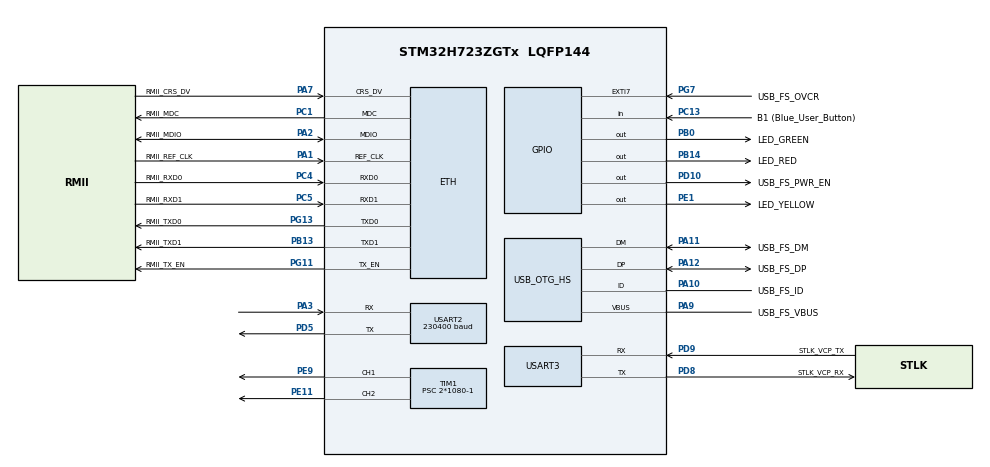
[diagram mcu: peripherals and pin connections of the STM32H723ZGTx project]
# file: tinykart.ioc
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Dma.Request0=USART2_RX
Dma.USART2_RX.0.Direction=DMA_PERIPH_TO_MEMORY
Dma.USART2_RX.0.EventEnable=DISABLE
Dma.USART2_RX.0.FIFOMode=DMA_FIFOMODE_DISABLE
Dma.USART2_RX.0.Instance=DMA1_Stream0
Dma.USART2_RX.0.MemDataAlignment=DMA_MDATAALIGN_BYTE
Dma.USART2_RX.0.MemInc=DMA_MINC_ENABLE
Dma.USART2_RX.0.Mode=DMA_NORMAL
Dma.USART2_RX.0.PeriphDataAlignment=DMA_PDATAALIGN_BYTE
Dma.USART2_RX.0.PeriphInc=DMA_PINC_DISABLE
Dma.USART2_RX.0.Polarity=HAL_DMAMUX_REQ_GEN_RISING
Dma.USART2_RX.0.Priority=DMA_PRIORITY_LOW
Dma.USART2_RX.0.RequestNumber=1
Dma.USART2_RX.0.SignalID=NONE
Dma.USART2_RX.0.SyncEnable=DISABLE
Dma.USART2_RX.0.SyncPolarity=HAL_DMAMUX_SYNC_NO_EVENT
Dma.USART2_RX.0.SyncRequestNumber=1
Dma.USART2_RX.0.SyncSignalID=NONE
ETH.MediaInterface=HAL_ETH_RMII_MODE
Mcu.Family=STM32H7
Mcu.Name=STM32H723ZGTx
Mcu.Package=LQFP144
NVIC.DMA1_Stream0_IRQn=true\:0\:0\:false\:false\:true\:false\:true\:true
NVIC.PriorityGroup=NVIC_PRIORITYGROUP_4
NVIC.USART2_IRQn=true\:0\:0\:false\:false\:true\:true\:true\:true
PA1.GPIO_Label=RMII_REF_CLK
PA1.Mode=RMII
PA1.Signal=ETH_REF_CLK
PA10.GPIO_Label=USB_FS_ID
PA10.Mode=OTG/Dual-Role-Device-FS
PA10.Signal=USB_OTG_HS_ID
PA11.GPIO_Label=USB_FS_DM
PA11.Mode=OTG/Dual-Role-Device-FS
PA11.Signal=USB_OTG_HS_DM
PA12.GPIO_Label=USB_FS_DP
PA12.Mode=OTG/Dual-Role-Device-FS
PA12.Signal=USB_OTG_HS_DP
PA13(JTMS/SWDIO).GPIO_Label=SWDIO
PA13(JTMS/SWDIO).Mode=Trace_Asynchronous_SW
PA13(JTMS/SWDIO).Signal=DEBUG_JTMS-SWDIO
PA14(JTCK/SWCLK).GPIO_Label=SWCLK
PA14(JTCK/SWCLK).Mode=Trace_Asynchronous_SW
PA14(JTCK/SWCLK).Signal=DEBUG_JTCK-SWCLK
PA2.GPIO_Label=RMII_MDIO
PA2.Mode=RMII
PA2.Signal=ETH_MDIO
PA3.Mode=Asynchronous
PA3.Signal=USART2_RX
PA7.GPIO_Label=RMII_CRS_DV
PA7.Mode=RMII
PA7.Signal=ETH_CRS_DV
PA9.GPIO_Label=USB_FS_VBUS
PA9.Mode=Activate_VBUS_FS
PA9.Signal=USB_OTG_HS_VBUS
PB0.GPIO_Label=LED_GREEN
PB0.Signal=GPIO_Output
PB13.GPIO_Label=RMII_TXD1
PB13.Mode=RMII
PB13.Signal=ETH_TXD1
PB14.GPIO_Label=LED_RED
PB14.Signal=GPIO_Output
PB3(JTDO/TRACESWO).GPIO_Label=SWO
PB3(JTDO/TRACESWO).Mode=Trace_Asynchronous_SW
PB3(JTDO/TRACESWO).Signal=DEBUG_JTDO-SWO
PC1.GPIO_Label=RMII_MDC
PC1.Mode=RMII
PC1.Signal=ETH_MDC
PC13.GPIO_Label=B1 (Blue_User_Button)
PC13.Signal=GPIO_Input
PC14-OSC32_IN.Mode=LSE-External-Oscillator
PC14-OSC32_IN.Signal=RCC_OSC32_IN
PC15-OSC32_OUT.Mode=LSE-External-Oscillator
PC15-OSC32_OUT.Signal=RCC_OSC32_OUT
PC4.GPIO_Label=RMII_RXD0
PC4.Mode=RMII
PC4.Signal=ETH_RXD0
PC5.GPIO_Label=RMII_RXD1
PC5.Mode=RMII
PC5.Signal=ETH_RXD1
PD10.GPIO_Label=USB_FS_PWR_EN
PD10.Signal=GPIO_Output
PD5.Mode=Asynchronous
PD5.Signal=USART2_TX
PD8.GPIO_Label=STLK_VCP_RX
PD8.Mode=Asynchronous
PD8.Signal=USART3_TX
PD9.GPIO_Label=STLK_VCP_TX
PD9.Mode=Asynchronous
PD9.Signal=USART3_RX
PE1.GPIO_Label=LED_YELLOW
PE1.Signal=GPIO_Output
PE11.Signal=S_TIM1_CH2
PE9.Signal=S_TIM1_CH1
PG11.GPIO_Label=RMII_TX_EN
PG11.Mode=RMII
PG11.Signal=ETH_TX_EN
PG13.GPIO_Label=RMII_TXD0
PG13.Mode=RMII
PG13.Signal=ETH_TXD0
PG7.GPIO_Label=USB_FS_OVCR
PG7.Signal=GPXTI7
PH0-OSC_IN.GPIO_Label=MCO
PH0-OSC_IN.Mode=HSE-External-Oscillator
PH0-OSC_IN.Signal=RCC_OSC_IN
PH1-OSC_OUT.Mode=HSE-External-Oscillator
PH1-OSC_OUT.Signal=RCC_OSC_OUT
ProjectManager.HeapSize=0x200
ProjectManager.StackSize=0x400
ProjectManager.TargetToolchain=STM32CubeIDE
RCC.ADCFreq_Value=76000000
RCC.APB1Freq_Value=54000000
RCC.APB2Freq_Value=108000000
RCC.APB3Freq_Value=108000000
RCC.APB4Freq_Value=108000000
RCC.CortexFreq_Value=216000000
RCC.D1PPRE=RCC_APB3_DIV2
RCC.D2PPRE1=RCC_APB1_DIV4
RCC.D2PPRE2=RCC_APB2_DIV2
RCC.D3PPRE=RCC_APB4_DIV2
RCC.DIVM1=1
RCC.DIVM2=1
RCC.DIVN1=27
RCC.DIVN2=19
RCC.DIVP1=1
RCC.DIVQ1=4
RCC.HCLKFreq_Value=216000000
RCC.HSE_VALUE=8000000
RCC.PLLFRACN=0
RCC.PLLSourceVirtual=RCC_PLLSOURCE_HSE
RCC.SYSCLKFreq_VALUE=216000000
RCC.SYSCLKSource=RCC_SYSCLKSOURCE_PLLCLK
RCC.USBCLockSelection=RCC_USBCLKSOURCE_HSI48
RCC.USBFreq_Value=48000000
SH.S_TIM1_CH1.0=TIM1_CH1,PWM Generation1 CH1
SH.S_TIM1_CH2.0=TIM1_CH2,PWM Generation2 CH2
TIM1.Channel-PWM\ Generation1\ CH1=TIM_CHANNEL_1
TIM1.Channel-PWM\ Generation2\ CH2=TIM_CHANNEL_2
TIM1.Period=1000-1
TIM1.Prescaler=2*1080-1
USART2.BaudRate=230400
USART2.VirtualMode-Asynchronous=VM_ASYNC
USART3.VirtualMode-Asynchronous=VM_ASYNC
board=NUCLEO-H723ZG

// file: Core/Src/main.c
/* USER CODE BEGIN Header */
/**
 ******************************************************************************
 * @file           : main.c
 * @brief          : Main program body
 ******************************************************************************
 * @attention
 *
 * Copyright (c) 2023 STMicroelectronics.
 * All rights reserved.
 *
 * This software is licensed under terms that can be found in the LICENSE file
 * in the root directory of this software component.
 * If no LICENSE file comes with this software, it is provided AS-IS.
 *
 ******************************************************************************
 */
/* USER CODE END Header */
#include "main.h"
#include "string.h"
#include <stdio.h>

#if defined ( __ICCARM__ ) /*!< IAR Compiler */
#pragma location=0x30000000
ETH_DMADescTypeDef  DMARxDscrTab[ETH_RX_DESC_CNT]; /* Ethernet Rx DMA Descriptors */
#pragma location=0x30000200
ETH_DMADescTypeDef  DMATxDscrTab[ETH_TX_DESC_CNT]; /* Ethernet Tx DMA Descriptors */

#elif defined ( __CC_ARM )  /* MDK ARM Compiler */

__attribute__((at(0x30000000))) ETH_DMADescTypeDef  DMARxDscrTab[ETH_RX_DESC_CNT]; /* Ethernet Rx DMA Descriptors */
__attribute__((at(0x30000200))) ETH_DMADescTypeDef  DMATxDscrTab[ETH_TX_DESC_CNT]; /* Ethernet Tx DMA Descriptors */

#elif defined ( __GNUC__ ) /* GNU Compiler */
ETH_DMADescTypeDef DMARxDscrTab[ETH_RX_DESC_CNT] __attribute__((section(".RxDecripSection"))); /* Ethernet Rx DMA Descriptors */
ETH_DMADescTypeDef DMATxDscrTab[ETH_TX_DESC_CNT] __attribute__((section(".TxDecripSection"))); /* Ethernet Tx DMA Descriptors */

#endif

ETH_TxPacketConfig TxConfig;

ETH_HandleTypeDef heth;

TIM_HandleTypeDef htim1;

UART_HandleTypeDef huart2;
UART_HandleTypeDef huart3;
DMA_HandleTypeDef hdma_usart2_rx;

void SystemClock_Config(void);
static void MX_GPIO_Init(void);
static void MX_DMA_Init(void);
static void MX_USART3_UART_Init(void);
static void MX_USB_OTG_HS_USB_Init(void);
static void MX_TIM1_Init(void);
static void MX_USART2_UART_Init(void);
static void MX_ETH_Init(void);

/* USER CODE BEGIN 0 */

uint8_t rx_indx;
uint8_t rx_data[11];
uint8_t rx_buffer[47];
uint8_t transfer_cplt;

int _write(int file, char *ptr, int len) {
		HAL_UART_Transmit(&huart2, (uint8_t*)ptr, len, HAL_MAX_DELAY);
		return len;
}

/* USER CODE END 0 */

int main(void) {

	/* MCU Configuration--------------------------------------------------------*/

	/* Reset of all peripherals, Initializes the Flash interface and the Systick. */
	HAL_Init();

	/* USER CODE BEGIN Init */
	HAL_TIM_PWM_Start(&htim1, 1);

	/* USER CODE END Init */

	/* Configure the system clock */
	SystemClock_Config();

	/* Initialize all configured peripherals */
	MX_GPIO_Init();
	MX_DMA_Init();
	MX_USART3_UART_Init();
	MX_USB_OTG_HS_USB_Init();
	MX_TIM1_Init();
	MX_USART2_UART_Init();
	MX_ETH_Init();

	/* Infinite loop */
	while (1) {

		HAL_UART_Receive_DMA(&huart2, rx_buffer, 47);

		printf("hi");
		HAL_Delay(500);

	}
}

void SystemClock_Config(void) {
	RCC_OscInitTypeDef RCC_OscInitStruct = { 0 };
	RCC_ClkInitTypeDef RCC_ClkInitStruct = { 0 };

	/** Supply configuration update enable
	 */
	HAL_PWREx_ConfigSupply(PWR_LDO_SUPPLY);

	/** Configure the main internal regulator output voltage
	 */
	__HAL_PWR_VOLTAGESCALING_CONFIG(PWR_REGULATOR_VOLTAGE_SCALE2);

	while (!__HAL_PWR_GET_FLAG(PWR_FLAG_VOSRDY)) {
	}

	/** Initializes the RCC Oscillators according to the specified parameters
	 * in the RCC_OscInitTypeDef structure.
	 */
	RCC_OscInitStruct.OscillatorType = RCC_OSCILLATORTYPE_HSI48
			| RCC_OSCILLATORTYPE_HSE;
	RCC_OscInitStruct.HSEState = RCC_HSE_ON;
	RCC_OscInitStruct.HSI48State = RCC_HSI48_ON;
	RCC_OscInitStruct.PLL.PLLState = RCC_PLL_ON;
	RCC_OscInitStruct.PLL.PLLSource = RCC_PLLSOURCE_HSE;
	RCC_OscInitStruct.PLL.PLLM = 1;
	RCC_OscInitStruct.PLL.PLLN = 27;
	RCC_OscInitStruct.PLL.PLLP = 1;
	RCC_OscInitStruct.PLL.PLLQ = 4;
	RCC_OscInitStruct.PLL.PLLR = 2;
	RCC_OscInitStruct.PLL.PLLRGE = RCC_PLL1VCIRANGE_3;
	RCC_OscInitStruct.PLL.PLLVCOSEL = RCC_PLL1VCOWIDE;
	RCC_OscInitStruct.PLL.PLLFRACN = 0;
	if (HAL_RCC_OscConfig(&RCC_OscInitStruct) != HAL_OK) {
		Error_Handler();
	}

	/** Initializes the CPU, AHB and APB buses clocks
	 */
	RCC_ClkInitStruct.ClockType = RCC_CLOCKTYPE_HCLK | RCC_CLOCKTYPE_SYSCLK
			| RCC_CLOCKTYPE_PCLK1 | RCC_CLOCKTYPE_PCLK2 | RCC_CLOCKTYPE_D3PCLK1
			| RCC_CLOCKTYPE_D1PCLK1;
	RCC_ClkInitStruct.SYSCLKSource = RCC_SYSCLKSOURCE_PLLCLK;
	RCC_ClkInitStruct.SYSCLKDivider = RCC_SYSCLK_DIV1;
	RCC_ClkInitStruct.AHBCLKDivider = RCC_HCLK_DIV1;
	RCC_ClkInitStruct.APB3CLKDivider = RCC_APB3_DIV2;
	RCC_ClkInitStruct.APB1CLKDivider = RCC_APB1_DIV4;
	RCC_ClkInitStruct.APB2CLKDivider = RCC_APB2_DIV2;
	RCC_ClkInitStruct.APB4CLKDivider = RCC_APB4_DIV2;

	if (HAL_RCC_ClockConfig(&RCC_ClkInitStruct, FLASH_LATENCY_0) != HAL_OK) {
		Error_Handler();
	}
}

static void MX_ETH_Init(void) {

	static uint8_t MACAddr[6];

	heth.Instance = ETH;
	MACAddr[0] = 0x00;
	MACAddr[1] = 0x80;
	MACAddr[2] = 0xE1;
	MACAddr[3] = 0x00;
	MACAddr[4] = 0x00;
	MACAddr[5] = 0x00;
	heth.Init.MACAddr = &MACAddr[0];
	heth.Init.MediaInterface = HAL_ETH_RMII_MODE;
	heth.Init.TxDesc = DMATxDscrTab;
	heth.Init.RxDesc = DMARxDscrTab;
	heth.Init.RxBuffLen = 1524;

	if (HAL_ETH_Init(&heth) != HAL_OK) {
		Error_Handler();
	}

	memset(&TxConfig, 0, sizeof(ETH_TxPacketConfig));
	TxConfig.Attributes = ETH_TX_PACKETS_FEATURES_CSUM
			| ETH_TX_PACKETS_FEATURES_CRCPAD;
	TxConfig.ChecksumCtrl = ETH_CHECKSUM_IPHDR_PAYLOAD_INSERT_PHDR_CALC;
	TxConfig.CRCPadCtrl = ETH_CRC_PAD_INSERT;

}

static void MX_TIM1_Init(void) {

	TIM_MasterConfigTypeDef sMasterConfig = { 0 };
	TIM_OC_InitTypeDef sConfigOC = { 0 };
	TIM_BreakDeadTimeConfigTypeDef sBreakDeadTimeConfig = { 0 };

	htim1.Instance = TIM1;
	htim1.Init.Prescaler = 2 * 1080 - 1;
	htim1.Init.CounterMode = TIM_COUNTERMODE_UP;
	htim1.Init.Period = 1000 - 1;
	htim1.Init.ClockDivision = TIM_CLOCKDIVISION_DIV1;
	htim1.Init.RepetitionCounter = 0;
	htim1.Init.AutoReloadPreload = TIM_AUTORELOAD_PRELOAD_DISABLE;
	if (HAL_TIM_PWM_Init(&htim1) != HAL_OK) {
		Error_Handler();
	}
	sMasterConfig.MasterOutputTrigger = TIM_TRGO_RESET;
	sMasterConfig.MasterOutputTrigger2 = TIM_TRGO2_RESET;
	sMasterConfig.MasterSlaveMode = TIM_MASTERSLAVEMODE_DISABLE;
	if (HAL_TIMEx_MasterConfigSynchronization(&htim1, &sMasterConfig)
			!= HAL_OK) {
		Error_Handler();
	}
	sConfigOC.OCMode = TIM_OCMODE_PWM1;
	sConfigOC.Pulse = 0;
	sConfigOC.OCPolarity = TIM_OCPOLARITY_HIGH;
	sConfigOC.OCNPolarity = TIM_OCNPOLARITY_HIGH;
	sConfigOC.OCFastMode = TIM_OCFAST_DISABLE;
	sConfigOC.OCIdleState = TIM_OCIDLESTATE_RESET;
	sConfigOC.OCNIdleState = TIM_OCNIDLESTATE_RESET;
	if (HAL_TIM_PWM_ConfigChannel(&htim1, &sConfigOC, TIM_CHANNEL_1)
			!= HAL_OK) {
		Error_Handler();
	}
	if (HAL_TIM_PWM_ConfigChannel(&htim1, &sConfigOC, TIM_CHANNEL_2)
			!= HAL_OK) {
		Error_Handler();
	}
	sBreakDeadTimeConfig.OffStateRunMode = TIM_OSSR_DISABLE;
	sBreakDeadTimeConfig.OffStateIDLEMode = TIM_OSSI_DISABLE;
	sBreakDeadTimeConfig.LockLevel = TIM_LOCKLEVEL_OFF;
	sBreakDeadTimeConfig.DeadTime = 0;
	sBreakDeadTimeConfig.BreakState = TIM_BREAK_DISABLE;
	sBreakDeadTimeConfig.BreakPolarity = TIM_BREAKPOLARITY_HIGH;
	sBreakDeadTimeConfig.BreakFilter = 0;
	sBreakDeadTimeConfig.Break2State = TIM_BREAK2_DISABLE;
	sBreakDeadTimeConfig.Break2Polarity = TIM_BREAK2POLARITY_HIGH;
	sBreakDeadTimeConfig.Break2Filter = 0;
	sBreakDeadTimeConfig.AutomaticOutput = TIM_AUTOMATICOUTPUT_DISABLE;
	if (HAL_TIMEx_ConfigBreakDeadTime(&htim1, &sBreakDeadTimeConfig)
			!= HAL_OK) {
		Error_Handler();
	}
	HAL_TIM_MspPostInit(&htim1);

}

static void MX_USART2_UART_Init(void) {

	huart2.Instance = USART2;
	huart2.Init.BaudRate = 230400;
	huart2.Init.WordLength = UART_WORDLENGTH_8B;
	huart2.Init.StopBits = UART_STOPBITS_1;
	huart2.Init.Parity = UART_PARITY_NONE;
	huart2.Init.Mode = UART_MODE_TX_RX;
	huart2.Init.HwFlowCtl = UART_HWCONTROL_NONE;
	huart2.Init.OverSampling = UART_OVERSAMPLING_16;
	huart2.Init.OneBitSampling = UART_ONE_BIT_SAMPLE_DISABLE;
	huart2.Init.ClockPrescaler = UART_PRESCALER_DIV1;
	huart2.AdvancedInit.AdvFeatureInit = UART_ADVFEATURE_NO_INIT;
	if (HAL_UART_Init(&huart2) != HAL_OK) {
		Error_Handler();
	}
	if (HAL_UARTEx_SetTxFifoThreshold(&huart2, UART_TXFIFO_THRESHOLD_1_8)
			!= HAL_OK) {
		Error_Handler();
	}
	if (HAL_UARTEx_SetRxFifoThreshold(&huart2, UART_RXFIFO_THRESHOLD_1_8)
			!= HAL_OK) {
		Error_Handler();
	}
	if (HAL_UARTEx_DisableFifoMode(&huart2) != HAL_OK) {
		Error_Handler();
	}

}

static void MX_USART3_UART_Init(void) {

	huart3.Instance = USART3;
	huart3.Init.BaudRate = 115200;
	huart3.Init.WordLength = UART_WORDLENGTH_8B;
	huart3.Init.StopBits = UART_STOPBITS_1;
	huart3.Init.Parity = UART_PARITY_NONE;
	huart3.Init.Mode = UART_MODE_TX_RX;
	huart3.Init.HwFlowCtl = UART_HWCONTROL_NONE;
	huart3.Init.OverSampling = UART_OVERSAMPLING_16;
	huart3.Init.OneBitSampling = UART_ONE_BIT_SAMPLE_DISABLE;
	huart3.Init.ClockPrescaler = UART_PRESCALER_DIV1;
	huart3.AdvancedInit.AdvFeatureInit = UART_ADVFEATURE_NO_INIT;
	if (HAL_UART_Init(&huart3) != HAL_OK) {
		Error_Handler();
	}
	if (HAL_UARTEx_SetTxFifoThreshold(&huart3, UART_TXFIFO_THRESHOLD_1_8)
			!= HAL_OK) {
		Error_Handler();
	}
	if (HAL_UARTEx_SetRxFifoThreshold(&huart3, UART_RXFIFO_THRESHOLD_1_8)
			!= HAL_OK) {
		Error_Handler();
	}
	if (HAL_UARTEx_DisableFifoMode(&huart3) != HAL_OK) {
		Error_Handler();
	}

}

static void MX_USB_OTG_HS_USB_Init(void) {

}

static void MX_DMA_Init(void) {

	/* DMA controller clock enable */
	__HAL_RCC_DMA1_CLK_ENABLE();

	/* DMA interrupt init */
	/* DMA1_Stream0_IRQn interrupt configuration */
	HAL_NVIC_SetPriority(DMA1_Stream0_IRQn, 0, 0);
	HAL_NVIC_EnableIRQ(DMA1_Stream0_IRQn);

}

static void MX_GPIO_Init(void) {
	GPIO_InitTypeDef GPIO_InitStruct = { 0 };

	/* GPIO Ports Clock Enable */
	__HAL_RCC_GPIOC_CLK_ENABLE();
	__HAL_RCC_GPIOH_CLK_ENABLE();
	__HAL_RCC_GPIOA_CLK_ENABLE();
	__HAL_RCC_GPIOB_CLK_ENABLE();
	__HAL_RCC_GPIOE_CLK_ENABLE();
	__HAL_RCC_GPIOD_CLK_ENABLE();
	__HAL_RCC_GPIOG_CLK_ENABLE();

	/*Configure GPIO pin Output Level */
	HAL_GPIO_WritePin(GPIOB, LED_GREEN_Pin | LED_RED_Pin, GPIO_PIN_RESET);

	/*Configure GPIO pin Output Level */
	HAL_GPIO_WritePin(USB_FS_PWR_EN_GPIO_Port, USB_FS_PWR_EN_Pin,
			GPIO_PIN_RESET);

	/*Configure GPIO pin Output Level */
	HAL_GPIO_WritePin(LED_YELLOW_GPIO_Port, LED_YELLOW_Pin, GPIO_PIN_RESET);

	/*Configure GPIO pin : B1_Pin */
	GPIO_InitStruct.Pin = B1_Pin;
	GPIO_InitStruct.Mode = GPIO_MODE_INPUT;
	GPIO_InitStruct.Pull = GPIO_NOPULL;
	HAL_GPIO_Init(B1_GPIO_Port, &GPIO_InitStruct);

	/*Configure GPIO pins : LED_GREEN_Pin LED_RED_Pin */
	GPIO_InitStruct.Pin = LED_GREEN_Pin | LED_RED_Pin;
	GPIO_InitStruct.Mode = GPIO_MODE_OUTPUT_PP;
	GPIO_InitStruct.Pull = GPIO_NOPULL;
	GPIO_InitStruct.Speed = GPIO_SPEED_FREQ_LOW;
	HAL_GPIO_Init(GPIOB, &GPIO_InitStruct);

	/*Configure GPIO pin : USB_FS_PWR_EN_Pin */
	GPIO_InitStruct.Pin = USB_FS_PWR_EN_Pin;
	GPIO_InitStruct.Mode = GPIO_MODE_OUTPUT_PP;
	GPIO_InitStruct.Pull = GPIO_NOPULL;
	GPIO_InitStruct.Speed = GPIO_SPEED_FREQ_LOW;
	HAL_GPIO_Init(USB_FS_PWR_EN_GPIO_Port, &GPIO_InitStruct);

	/*Configure GPIO pin : USB_FS_OVCR_Pin */
	GPIO_InitStruct.Pin = USB_FS_OVCR_Pin;
	GPIO_InitStruct.Mode = GPIO_MODE_IT_RISING;
	GPIO_InitStruct.Pull = GPIO_NOPULL;
	HAL_GPIO_Init(USB_FS_OVCR_GPIO_Port, &GPIO_InitStruct);

	/*Configure GPIO pin : USB_FS_VBUS_Pin */
	GPIO_InitStruct.Pin = USB_FS_VBUS_Pin;
	GPIO_InitStruct.Mode = GPIO_MODE_INPUT;
	GPIO_InitStruct.Pull = GPIO_NOPULL;
	HAL_GPIO_Init(USB_FS_VBUS_GPIO_Port, &GPIO_InitStruct);

	/*Configure GPIO pin : USB_FS_ID_Pin */
	GPIO_InitStruct.Pin = USB_FS_ID_Pin;
	GPIO_InitStruct.Mode = GPIO_MODE_AF_PP;
	GPIO_InitStruct.Pull = GPIO_NOPULL;
	GPIO_InitStruct.Speed = GPIO_SPEED_FREQ_LOW;
	GPIO_InitStruct.Alternate = GPIO_AF10_OTG1_HS;
	HAL_GPIO_Init(USB_FS_ID_GPIO_Port, &GPIO_InitStruct);

	/*Configure GPIO pin : LED_YELLOW_Pin */
	GPIO_InitStruct.Pin = LED_YELLOW_Pin;
	GPIO_InitStruct.Mode = GPIO_MODE_OUTPUT_PP;
	GPIO_InitStruct.Pull = GPIO_NOPULL;
	GPIO_InitStruct.Speed = GPIO_SPEED_FREQ_LOW;
	HAL_GPIO_Init(LED_YELLOW_GPIO_Port, &GPIO_InitStruct);

}

/* USER CODE BEGIN 4 */

void HAL_UART_RxCpltCallback(UART_HandleTypeDef *huart)
{
  /* Prevent unused argument(s) compilation warning */
  UNUSED(huart);

  /* NOTE : This function should not be modified, when the callback is needed,
            the HAL_UART_RxCpltCallback can be implemented in the user file.
   */
}

/* USER CODE END 4 */

void Error_Handler(void) {
	__disable_irq();
	while (1) {
	}
}
